# N32H7xx register map
Vendor: Nationstech Ltd.; File version: 1.0
Registers are 32-bit, read-write, reset 0x0 unless marked. A register's access mark holds for its fields unless they carry their own. Offsets are from the block's base; [hi:lo] are bit positions; {n}, {i} and the like mark numbered series.

## MMU — Memory Manage Unit
Base 0x51105000
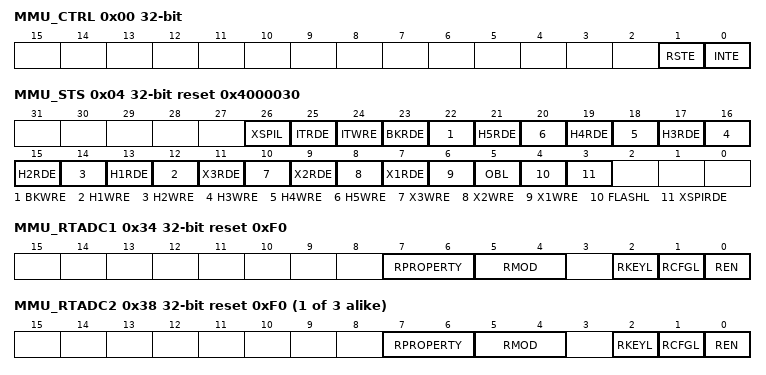
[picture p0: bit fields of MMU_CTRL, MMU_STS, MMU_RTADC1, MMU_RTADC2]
0x00 MMU_CTRL — MMU Control Register
  [1] RSTE, [0] INTE
0x04 MMU_STS reset 0x4000030 — MMU Status Register
  [26] XSPIL, [25] ITRDE, [24] ITWRE, [23] BKRDE, [22] BKWRE, [2n+11] H{n}RDE (n=1..5), [2n+10] H{n}WRE (n=1..5), [11] X3RDE, [10] X3WRE, [9] X2RDE, [8] X2WRE, [7] X1RDE, [6] X1WRE, [5] OBL, [4] FLASHL, [3] XSPIRDE
0x34 MMU_RTADC1 reset 0xF0 — Reserved, must keep reset value
  [7:6] RPROPERTY, [5:4] RMOD, [2] RKEYL, [1] RCFGL, [0] REN
{0x30+4i} MMU_RTADC{i} reset 0xF0 (i=2..4) — RTADC{i}
  [7:6] RPROPERTY, [5:4] RMOD, [2] RKEYL, [1] RCFGL, [0] REN
{0x34+0x10*i} MMU_RTK{i}P0 (i=1..4) — 1) RTAD_KEY1/2/3/4 Can be written by Anyone if RTAD_KEYx_LOCK=0 2) Can Not be Read by Anyone. Return 0, no bus error.
  [31:0] KEY
{0x38+0x10*i} MMU_RTK{i}P1 (i=1..4) — 1) RTAD_KEY1/2/3/4 Can be written by Anyone if RTAD_KEYx_LOCK=0 2) Can Not be Read by Anyone. Return 0, no bus error.
  [31:0] KEY
{0x3C+0x10*i} MMU_RTK{i}P2 (i=1..4) — 1) RTAD_KEY1/2/3/4 Can be written by Anyone if RTAD_KEYx_LOCK=0 2) Can Not be Read by Anyone. Return 0, no bus error.
  [31:0] KEY
{0x40+0x10*i} MMU_RTK{i}P3 (i=1..4) — 1) RTAD_KEY1/2/3/4 Can be written by Anyone if RTAD_KEYx_LOCK=0 2) Can Not be Read by Anyone. Return 0, no bus error.
  [31:0] KEY
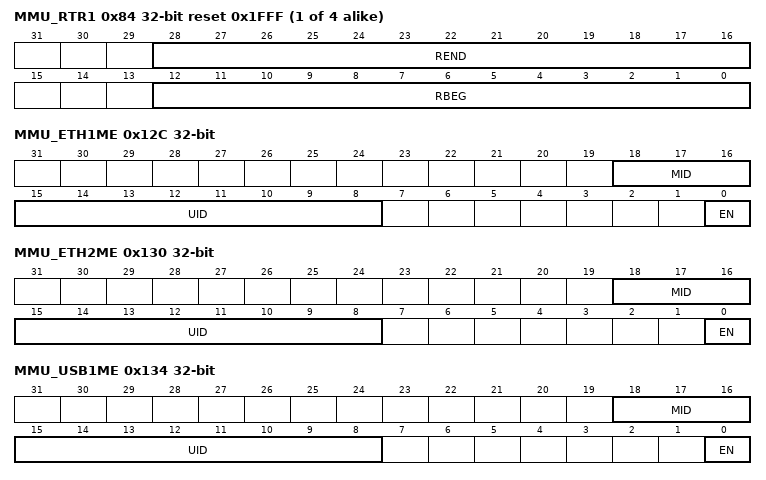
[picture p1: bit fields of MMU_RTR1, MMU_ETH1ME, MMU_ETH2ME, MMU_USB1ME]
{0x80+4i} MMU_RTR{i} reset 0x1FFF (i=1..4) — Can be written if RTAD_CFGx_LOCK=0
  [28:16] REND, [12:0] RBEG
0xB8 MMU_RTCRC reset 0xFFFFFFFF — RTCRC
  [31:0] CRC
0x12C MMU_ETH1ME — Disabling will reset master/user ID to 0
  [18:16] MID, [15:8] UID, [0] EN
0x130 MMU_ETH2ME — Disabling will reset master/user ID to 0
  [18:16] MID, [15:8] UID, [0] EN
0x134 MMU_USB1ME — Disabling will reset master/user ID to 0
  [18:16] MID, [15:8] UID, [0] EN
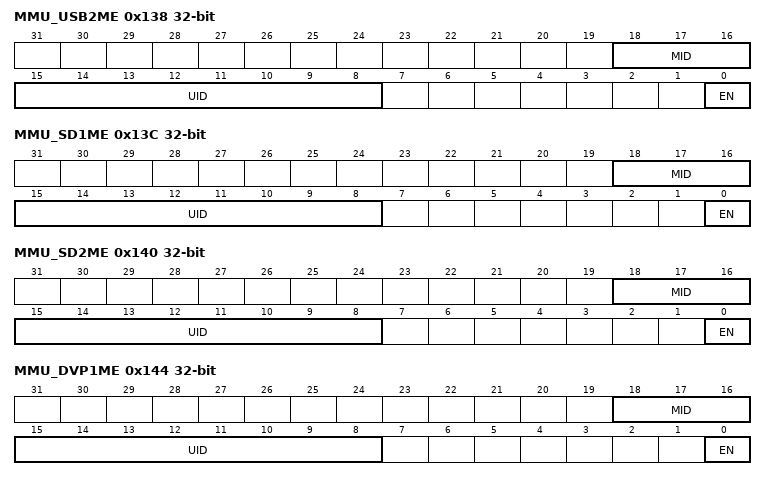
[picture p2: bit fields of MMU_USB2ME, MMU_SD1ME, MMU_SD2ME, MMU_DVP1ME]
0x138 MMU_USB2ME — Disabling will reset master/user ID to 0
  [18:16] MID, [15:8] UID, [0] EN
0x13C MMU_SD1ME — Disabling will reset master/user ID to 0
  [18:16] MID, [15:8] UID, [0] EN
0x140 MMU_SD2ME — Disabling will reset master/user ID to 0
  [18:16] MID, [15:8] UID, [0] EN
0x144 MMU_DVP1ME — Disabling will reset master/user ID to 0
  [18:16] MID, [15:8] UID, [0] EN
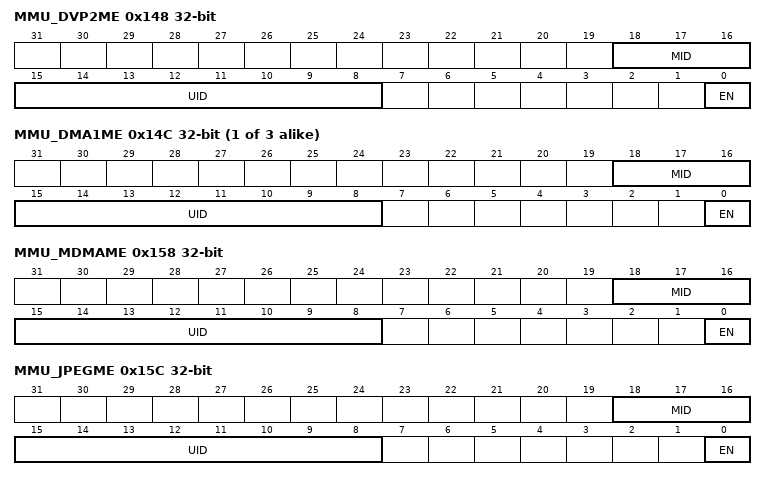
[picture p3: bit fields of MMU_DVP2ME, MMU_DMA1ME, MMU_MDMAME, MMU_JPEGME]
0x148 MMU_DVP2ME — Disabling will reset master/user ID to 0
  [18:16] MID, [15:8] UID, [0] EN
{0x148+4i} MMU_DMA{i}ME (i=1..3) — Disabling will reset master/user ID to 0
  [18:16] MID, [15:8] UID, [0] EN
0x158 MMU_MDMAME — Disabling will reset master/user ID to 0
  [18:16] MID, [15:8] UID, [0] EN
0x15C MMU_JPEGME — Disabling will reset master/user ID to 0
  [18:16] MID, [15:8] UID, [0] EN
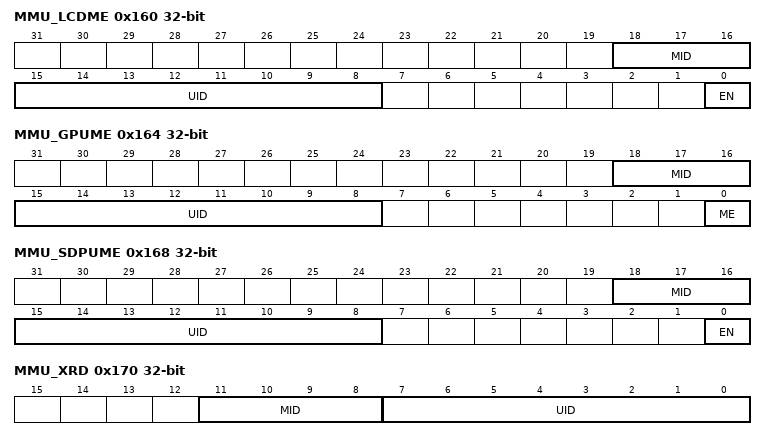
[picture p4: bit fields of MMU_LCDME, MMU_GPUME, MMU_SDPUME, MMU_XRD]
0x160 MMU_LCDME — Disabling will reset master/user ID to 0
  [18:16] MID, [15:8] UID, [0] EN
0x164 MMU_GPUME — Disabling will reset master/user ID to 0
  [18:16] MID, [15:8] UID, [0] ME
0x168 MMU_SDPUME — Disabling will reset master/user ID to 0
  [18:16] MID, [15:8] UID, [0] EN
0x170 MMU_XRD — XRD
  [11:8] MID, [7:0] UID
0x178 MMU_XRAD — XRAD
  [31:0] ADDR
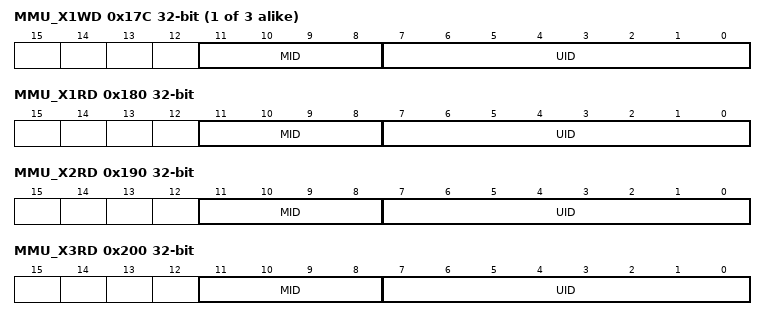
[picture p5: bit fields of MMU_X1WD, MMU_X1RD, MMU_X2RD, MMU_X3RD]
{0x16C+0x10*i} MMU_X{i}WD (i=1..3)
  [11:8] MID, [7:0] UID
0x180 MMU_X1RD
  [11:8] MID, [7:0] UID
0x184 MMU_X1WAD
  [31:0] ADDR
0x188 MMU_X1RAD
  [31:0] ADDR
0x190 MMU_X2RD
  [11:8] MID, [7:0] UID
0x194 MMU_X2WAD
  [31:0] ADDR
0x198 MMU_X2RAD
  [31:0] ADDR
0x200 MMU_X3RD
  [11:8] MID, [7:0] UID
0x204 MMU_X3WAD
  [31:0] ADDR
0x20C MMU_X3RAD
  [31:0] ADDR
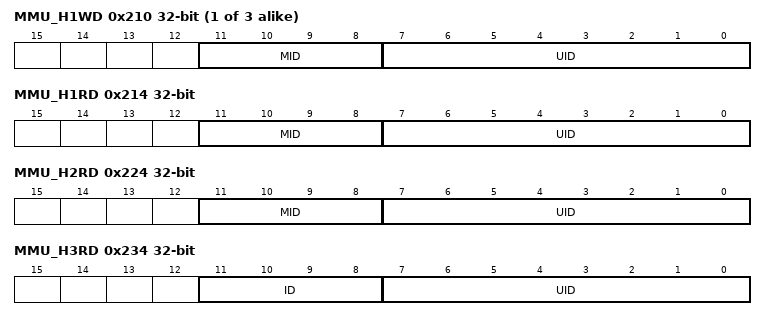
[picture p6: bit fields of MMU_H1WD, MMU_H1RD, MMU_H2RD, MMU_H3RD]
{0x200+0x10*i} MMU_H{i}WD (i=1..3)
  [11:8] MID, [7:0] UID
0x214 MMU_H1RD
  [11:8] MID, [7:0] UID
0x218 MMU_H1WAD
  [31:0] ADDDR
{0x20C+0x10*i} MMU_H{i}RAD (i=1..5)
  [31:0] ADDR
0x224 MMU_H2RD
  [11:8] MID, [7:0] UID
{0x208+0x10*i} MMU_H{i}WAD (i=2..5)
  [31:0] ADDR
0x234 MMU_H3RD
  [11:8] ID, [7:0] UID
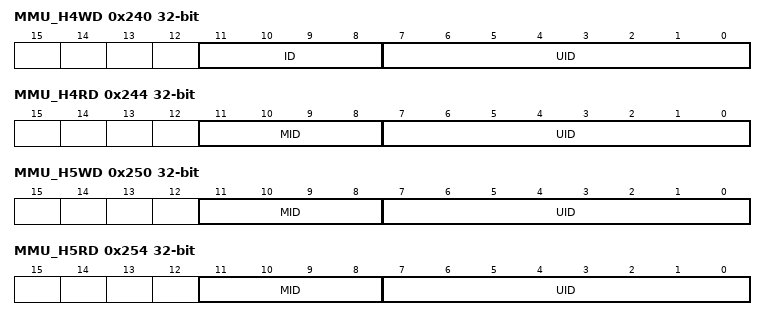
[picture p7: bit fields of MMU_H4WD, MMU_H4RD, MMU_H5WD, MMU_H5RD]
0x240 MMU_H4WD
  [11:8] ID, [7:0] UID
0x244 MMU_H4RD
  [11:8] MID, [7:0] UID
0x250 MMU_H5WD
  [11:8] MID, [7:0] UID
0x254 MMU_H5RD
  [11:8] MID, [7:0] UID
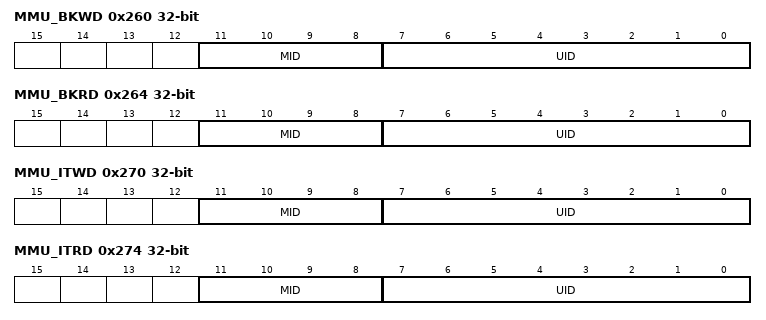
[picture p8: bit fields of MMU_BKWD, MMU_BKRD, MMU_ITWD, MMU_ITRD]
0x260 MMU_BKWD
  [11:8] MID, [7:0] UID
0x264 MMU_BKRD
  [11:8] MID, [7:0] UID
0x268 MMU_BKWAD
  [31:0] ADDR
0x26C MMU_BKRAD
  [31:0] ADDR
0x270 MMU_ITWD
  [11:8] MID, [7:0] UID
0x274 MMU_ITRD
  [11:8] MID, [7:0] UID
0x278 MMU_ITWAD
  [31:0] ADDR
0x27C MMU_ITRAD
  [31:0] ADDR
